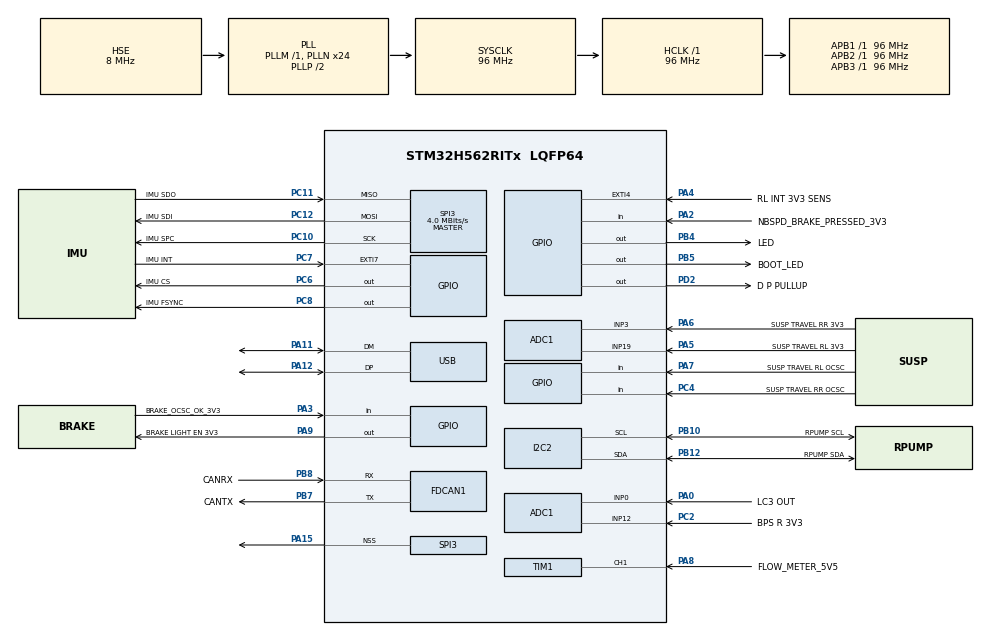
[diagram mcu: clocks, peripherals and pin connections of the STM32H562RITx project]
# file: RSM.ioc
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ADC1.Channel-0\#ChannelRegularConversion=ADC_CHANNEL_0
ADC1.Channel-1\#ChannelRegularConversion=ADC_CHANNEL_19
ADC1.Channel-2\#ChannelRegularConversion=ADC_CHANNEL_3
ADC1.Channel-3\#ChannelRegularConversion=ADC_CHANNEL_12
ADC1.ContinuousConvMode=DISABLE
ADC1.ConversionDataManagement=ADC_CONVERSIONDATA_DMA_CIRCULAR
ADC1.DMAContinuousRequests=ENABLE
ADC1.EOCSelection=ADC_EOC_SEQ_CONV
ADC1.ExternalTrigConv=ADC_EXTERNALTRIG_T3_TRGO
ADC1.MonitoredBy-0\#ChannelRegularConversion=__NULL
ADC1.MonitoredBy-1\#ChannelRegularConversion=__NULL
ADC1.MonitoredBy-2\#ChannelRegularConversion=__NULL
ADC1.MonitoredBy-3\#ChannelRegularConversion=__NULL
ADC1.NbrOfConversion=4
ADC1.NbrOfConversionFlag=1
ADC1.OffsetNumber-0\#ChannelRegularConversion=ADC_OFFSET_NONE
ADC1.OffsetNumber-1\#ChannelRegularConversion=ADC_OFFSET_NONE
ADC1.OffsetNumber-2\#ChannelRegularConversion=ADC_OFFSET_NONE
ADC1.OffsetNumber-3\#ChannelRegularConversion=ADC_OFFSET_NONE
ADC1.Rank-0\#ChannelRegularConversion=1
ADC1.Rank-1\#ChannelRegularConversion=2
ADC1.Rank-2\#ChannelRegularConversion=3
ADC1.Rank-3\#ChannelRegularConversion=4
ADC1.SamplingTime-0\#ChannelRegularConversion=ADC_SAMPLETIME_2CYCLES_5
ADC1.SamplingTime-1\#ChannelRegularConversion=ADC_SAMPLETIME_47CYCLES_5
ADC1.SamplingTime-2\#ChannelRegularConversion=ADC_SAMPLETIME_47CYCLES_5
ADC1.SamplingTime-3\#ChannelRegularConversion=ADC_SAMPLETIME_47CYCLES_5
ADC1.master=1
BOOTPATH.BootPathName=LEGACY
BOOTPATH.UserSelectedBootPath=LEGACY
CORTEX_M33_NS.userName=CORTEX_M33
FDCAN1.AutoRetransmission=ENABLE
FDCAN1.CalculateBaudRateNominal=1000000
FDCAN1.CalculateTimeBitNominal=1000
FDCAN1.CalculateTimeQuantumNominal=62.5
FDCAN1.DataPrescaler=3
FDCAN1.DataSyncJumpWidth=2
FDCAN1.DataTimeSeg1=5
FDCAN1.DataTimeSeg2=2
FDCAN1.ExtFiltersNbr=1
FDCAN1.FrameFormat=FDCAN_FRAME_FD_NO_BRS
FDCAN1.NominalPrescaler=6
FDCAN1.NominalSyncJumpWidth=2
FDCAN1.NominalTimeSeg1=13
FDCAN1.NominalTimeSeg2=2
FDCAN1.StdFiltersNbr=1
GPDMA1.CIRCULARMODE_GPDMACH0=ENABLE
GPDMA1.DESTDATAWIDTH_GPDMACH0=DMA_DEST_DATAWIDTH_HALFWORD
GPDMA1.DESTINC_GPDMACH0=DMA_DINC_INCREMENTED
GPDMA1.IPHANDLE_GPDMACH0-SIMPLEREQUEST_GPDMACH0=__NULL
GPDMA1.REQUEST_GPDMACH0=GPDMA1_REQUEST_ADC1
GPDMA1.SRCDATAWIDTH_GPDMACH0=DMA_SRC_DATAWIDTH_HALFWORD
GPDMA1.SRCINC_GPDMACH0=DMA_SINC_FIXED
I2C2.Timing=0x10B0DCFB
IWDG.Reload=LSI_FREQUENCY / IWDG_PRESCALER / IWDG_RESET_FREQUENCY
Mcu.Family=STM32H5
Mcu.Name=STM32H562RITx
Mcu.Package=LQFP64
Mcu.UserConstants=IWDG_RESET_FREQUENCY,5;TIM1_FREQUENCY,1000;TIM3_PRESCALER,250;TIM3_ARR,(TIMx_FREQUENCY / TIM3_PRESCALER / TIM3_FREQUENCY);TIM3_FREQUENCY,10000;TIM1_ARR,(TIMx_FREQUENCY / TIM1_PRESCALER / TIM1_FREQUENCY);IWDG_PRESCALER,4;LSI_FREQUENCY,32000;TIM1_PRESCALER,250;TIMx_FREQUENCY,250000000
NVIC.ADC1_IRQn=true\:5\:0\:true\:false\:true\:true\:true\:true
NVIC.FDCAN1_IT0_IRQn=true\:5\:0\:true\:false\:true\:true\:true\:true
NVIC.FDCAN1_IT1_IRQn=true\:5\:0\:true\:false\:true\:true\:true\:true
NVIC.GPDMA1_Channel0_IRQn=true\:5\:0\:true\:false\:true\:false\:true\:true
NVIC.I2C2_ER_IRQn=true\:5\:0\:true\:false\:true\:true\:true\:true
NVIC.I2C2_EV_IRQn=true\:5\:0\:true\:false\:true\:true\:true\:true
NVIC.PriorityGroup=NVIC_PRIORITYGROUP_4
NVIC.SPI3_IRQn=true\:5\:0\:true\:false\:true\:true\:true\:true
NVIC.TIM1_CC_IRQn=true\:0\:0\:false\:false\:true\:true\:true\:true
NVIC.TIM1_UP_IRQn=true\:0\:0\:false\:false\:true\:true\:true\:true
NVIC.TIM3_IRQn=true\:5\:0\:true\:false\:true\:true\:true\:true
NVIC.TIM6_IRQn=true\:15\:0\:false\:false\:true\:false\:true\:true
NVIC.TIM7_IRQn=true\:5\:0\:true\:false\:true\:true\:true\:true
NVIC.TimeBase=TIM6_IRQn
NVIC.TimeBaseIP=TIM6
NVIC.USB_DRD_FS_IRQn=true\:5\:0\:true\:false\:true\:true\:true\:true
PA0.GPIO_Label=LC3 OUT
PA0.Signal=ADCx_INP0
PA11.Mode=Device
PA11.Signal=USB_DM
PA12.Mode=Device
PA12.Signal=USB_DP
PA13(JTMS/SWDIO).Mode=Trace_Asynchronous_SW
PA13(JTMS/SWDIO).Signal=DEBUG_JTMS-SWDIO
PA14(JTCK/SWCLK).Mode=Trace_Asynchronous_SW
PA14(JTCK/SWCLK).Signal=DEBUG_JTCK-SWCLK
PA15(JTDI).Mode=NSS_Signal_Hard_Output
PA15(JTDI).Signal=SPI3_NSS
PA2.GPIO_Label=NBSPD_BRAKE_PRESSED_3V3
PA2.Signal=GPIO_Input
PA3.GPIO_Label=BRAKE_OCSC_OK_3V3
PA3.Signal=GPIO_Input
PA4.GPIO_Label=RL INT 3V3 SENS
PA4.Signal=GPXTI4
PA5.GPIO_Label=SUSP TRAVEL RL 3V3
PA5.Signal=ADCx_INP19
PA6.GPIO_Label=SUSP TRAVEL RR 3V3
PA6.Signal=ADCx_INP3
PA7.GPIO_Label=SUSP TRAVEL RL OCSC
PA7.Signal=GPIO_Input
PA8.GPIO_Label=FLOW_METER_5V5
PA8.Signal=S_TIM1_CH1
PA9.GPIO_Label=BRAKE LIGHT EN 3V3
PA9.Signal=GPIO_Output
PB10.GPIO_Label=RPUMP SCL
PB10.Mode=I2C
PB10.Signal=I2C2_SCL
PB12.GPIO_Label=RPUMP SDA
PB12.Mode=I2C
PB12.Signal=I2C2_SDA
PB3(JTDO/TRACESWO).Mode=Trace_Asynchronous_SW
PB3(JTDO/TRACESWO).Signal=DEBUG_JTDO-SWO
PB4(NJTRST).GPIO_Label=LED
PB4(NJTRST).Signal=GPIO_Output
PB5.GPIO_Label=BOOT_LED
PB5.Signal=GPIO_Output
PB7.GPIO_Label=CANTX
PB7.Mode=FDCAN_Activate
PB7.Signal=FDCAN1_TX
PB8.GPIO_Label=CANRX
PB8.Mode=FDCAN_Activate
PB8.Signal=FDCAN1_RX
PC10.GPIO_Label=IMU SPC
PC10.Mode=Full_Duplex_Master
PC10.Signal=SPI3_SCK
PC11.GPIO_Label=IMU SDO
PC11.Mode=Full_Duplex_Master
PC11.Signal=SPI3_MISO
PC12.GPIO_Label=IMU SDI
PC12.Mode=Full_Duplex_Master
PC12.Signal=SPI3_MOSI
PC2.GPIO_Label=BPS R 3V3
PC2.Signal=ADCx_INP12
PC4.GPIO_Label=SUSP TRAVEL RR OCSC
PC4.Signal=GPIO_Input
PC6.GPIO_Label=IMU CS
PC6.Signal=GPIO_Output
PC7.GPIO_Label=IMU INT
PC7.Signal=GPXTI7
PC8.GPIO_Label=IMU FSYNC
PC8.Signal=GPIO_Output
PD2.GPIO_Label=D P PULLUP
PD2.Signal=GPIO_Output
PH0-OSC_IN(PH0).Mode=HSE-External-Oscillator
PH0-OSC_IN(PH0).Signal=RCC_OSC_IN
PH1-OSC_OUT(PH1).Mode=HSE-External-Oscillator
PH1-OSC_OUT(PH1).Signal=RCC_OSC_OUT
ProjectManager.HeapSize=0x200
ProjectManager.StackSize=0x400
ProjectManager.TargetToolchain=EWARM V9.20
RCC.ADCFreq_Value=96000000
RCC.AHBFreq_Value=96000000
RCC.APB1Freq_Value=96000000
RCC.APB1TimFreq_Value=96000000
RCC.APB2Freq_Value=96000000
RCC.APB2TimFreq_Value=96000000
RCC.APB3Freq_Value=96000000
RCC.CSI_VALUE=4000000
RCC.CortexFreq_Value=96000000
RCC.EPOD_VALUE=8000000
RCC.FDCANClockSelection=RCC_FDCANCLKSOURCE_PLL1Q
RCC.HCLKFreq_Value=96000000
RCC.HSE_VALUE=8000000
RCC.HSI48_VALUE=48000000
RCC.HSI_VALUE=64000000
RCC.LSE_VALUE=32768
RCC.LSIRC_VALUE=32000
RCC.PLL2FRACN=0
RCC.PLL2N=32
RCC.PLL2P=16
RCC.PLL3FRACN=0
RCC.PLLFRACN=0
RCC.PLLN=24
RCC.PLLSourceVirtual=RCC_PLL1_SOURCE_HSE
RCC.SPI3CLockSelection=RCC_SPI3CLKSOURCE_PLL2P
RCC.SYSCLKFreq_VALUE=96000000
RCC.SYSCLKSource=RCC_SYSCLKSOURCE_PLLCLK
RCC.USBFreq_Value=48000000
RCC.VCOOutputFreq_Value=192000000
SH.ADCx_INP0.0=ADC1_INP0,IN0-Single-Ended
SH.ADCx_INP12.0=ADC1_INP12,IN12-Single-Ended
SH.ADCx_INP19.0=ADC1_INP19,IN19-Single-Ended
SH.ADCx_INP3.0=ADC1_INP3,IN3-Single-Ended
SH.S_TIM1_CH1.0=TIM1_CH1,Input_Capture1_from_TI1
SPI3.BaudRatePrescaler=SPI_BAUDRATEPRESCALER_2
SPI3.CalculateBaudRate=4.0 MBits/s
SPI3.DataSize=SPI_DATASIZE_8BIT
SPI3.Direction=SPI_DIRECTION_2LINES
SPI3.Mode=SPI_MODE_MASTER
SPI3.VirtualNSS=VM_NSSHARD
SPI3.VirtualType=VM_MASTER
TIM1.Channel-Input_Capture1_from_TI1=TIM_CHANNEL_1
TIM1.Channel-Input_Capture2_from_TI1_63=TIM_CHANNEL_2
TIM1.ICPolarity_CH2=TIM_INPUTCHANNELPOLARITY_FALLING
TIM1.PeriodNoDither=TIM1_ARR - 1
TIM1.Prescaler=TIM1_PRESCALER - 1
TIM3.AutoReloadPreload=TIM_AUTORELOAD_PRELOAD_ENABLE
TIM3.PeriodNoDither=TIM3_ARR - 1
TIM3.Prescaler=TIM3_PRESCALER - 1
TIM3.TIM_MasterOutputTrigger=TIM_TRGO_UPDATE
TIM3.TIM_MasterSlaveMode=TIM_MASTERSLAVEMODE_DISABLE
TIM7.PeriodNoDither=960-1
TIM7.Prescaler=10-1
USB.VirtualMode=Device_Only
VP_BOOTPATH_VS_BOOTPATH.Mode=BP_Activate
VP_CORTEX_M33_NS_VS_Hclk.Mode=Hclk_Mode
VP_GPDMA1_VS_GPDMACH0.Mode=SIMPLEREQUEST_GPDMACH0
VP_IWDG_VS_IWDG.Mode=IWDG_Activate
VP_MEMORYMAP_VS_MEMORYMAP.Mode=CurAppReg
VP_PWR_VS_LPOM.Mode=PowerOptimisation
VP_PWR_VS_SECSignals.Mode=Security/Privilege
VP_SYS_VS_tim6.Mode=TIM6
VP_TIM1_VS_ClockSourceINT.Mode=Internal
VP_TIM1_VS_indirect_ch1.Mode=Input_Capture2_from_TI1_63
VP_TIM3_VS_ClockSourceINT.Mode=Internal
VP_TIM7_VS_ClockSourceINT.Mode=Enable_Timer
board=custom

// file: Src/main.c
/* USER CODE BEGIN Header */
/**
 ******************************************************************************
 * @file           : main.c
 * @brief          : Main program body
 ******************************************************************************
 * @attention
 *
 * Copyright (c) 2025 STMicroelectronics.
 * All rights reserved.
 *
 * This software is licensed under terms that can be found in the LICENSE file
 * in the root directory of this software component.
 * If no LICENSE file comes with this software, it is provided AS-IS.
 *
 ******************************************************************************
 */
/* USER CODE END Header */
#include "main.h"

/* USER CODE BEGIN Includes */
#include "tasks.h"
#include <stm32h5xx_hal.h>
#include <stm32h5xx_hal_gpio.h>
#include "hw_error.hpp"
/* USER CODE END Includes */

ADC_HandleTypeDef hadc1;
DMA_NodeTypeDef   Node_GPDMA1_Channel0;
DMA_QListTypeDef  List_GPDMA1_Channel0;
DMA_HandleTypeDef handle_GPDMA1_Channel0;

FDCAN_HandleTypeDef hfdcan1;

I2C_HandleTypeDef hi2c2;

IWDG_HandleTypeDef hiwdg;

SPI_HandleTypeDef hspi3;

TIM_HandleTypeDef htim1;
TIM_HandleTypeDef htim3;
TIM_HandleTypeDef htim7;

PCD_HandleTypeDef hpcd_USB_DRD_FS;

void        SystemClock_Config(void);
static void MX_GPIO_Init(void);
static void MX_GPDMA1_Init(void);
static void MX_ADC1_Init(void);
static void MX_FDCAN1_Init(void);
static void MX_I2C2_Init(void);
static void MX_SPI3_Init(void);
static void MX_USB_PCD_Init(void);
static void MX_TIM1_Init(void);
static void MX_TIM3_Init(void);
static void MX_IWDG_Init(void);
static void MX_TIM7_Init(void);

int main(void)
{
    /* USER CODE BEGIN 1 */
    tasks_preInit();
    /* USER CODE END 1 */

    /* MCU Configuration--------------------------------------------------------*/

    /* Reset of all peripherals, Initializes the Flash interface and the Systick. */
    HAL_Init();

    /* Configure the system clock */
    SystemClock_Config();

    /* Initialize all configured peripherals */
    MX_GPIO_Init();
    MX_GPDMA1_Init();
    MX_ADC1_Init();
    MX_FDCAN1_Init();
    MX_I2C2_Init();
    MX_SPI3_Init();
    MX_USB_PCD_Init();
    MX_TIM1_Init();
    MX_TIM3_Init();
    MX_IWDG_Init();
    MX_TIM7_Init();
    /* USER CODE BEGIN 2 */
    HAL_GPIO_WritePin(BRAKE_LIGHT_EN_3V3_GPIO_Port, BRAKE_LIGHT_EN_3V3_Pin, GPIO_PIN_RESET);
    ;
    tasks_init();
    /* USER CODE END 2 */

    /* Infinite loop */
    while (1)
    {

    }
}

void SystemClock_Config(void)
{
    RCC_OscInitTypeDef RCC_OscInitStruct = { 0 };
    RCC_ClkInitTypeDef RCC_ClkInitStruct = { 0 };

    /** Configure the main internal regulator output voltage
     */
    __HAL_PWR_VOLTAGESCALING_CONFIG(PWR_REGULATOR_VOLTAGE_SCALE3);

    while (!__HAL_PWR_GET_FLAG(PWR_FLAG_VOSRDY))
    {
    }

    /** Initializes the RCC Oscillators according to the specified parameters
     * in the RCC_OscInitTypeDef structure.
     */
    RCC_OscInitStruct.OscillatorType =
        RCC_OSCILLATORTYPE_HSI48 | RCC_OSCILLATORTYPE_LSI | RCC_OSCILLATORTYPE_HSE | RCC_OSCILLATORTYPE_CSI;
    RCC_OscInitStruct.HSEState            = RCC_HSE_ON;
    RCC_OscInitStruct.LSIState            = RCC_LSI_ON;
    RCC_OscInitStruct.HSI48State          = RCC_HSI48_ON;
    RCC_OscInitStruct.CSIState            = RCC_CSI_ON;
    RCC_OscInitStruct.CSICalibrationValue = RCC_CSICALIBRATION_DEFAULT;
    RCC_OscInitStruct.PLL.PLLState        = RCC_PLL_ON;
    RCC_OscInitStruct.PLL.PLLSource       = RCC_PLL1_SOURCE_HSE;
    RCC_OscInitStruct.PLL.PLLM            = 1;
    RCC_OscInitStruct.PLL.PLLN            = 24;
    RCC_OscInitStruct.PLL.PLLP            = 2;
    RCC_OscInitStruct.PLL.PLLQ            = 2;
    RCC_OscInitStruct.PLL.PLLR            = 2;
    RCC_OscInitStruct.PLL.PLLRGE          = RCC_PLL1_VCIRANGE_3;
    RCC_OscInitStruct.PLL.PLLVCOSEL       = RCC_PLL1_VCORANGE_WIDE;
    RCC_OscInitStruct.PLL.PLLFRACN        = 0;
    if (HAL_RCC_OscConfig(&RCC_OscInitStruct) != HAL_OK)
    {
        Error_Handler();
    }

    /** Initializes the CPU, AHB and APB buses clocks
     */
    RCC_ClkInitStruct.ClockType =
        RCC_CLOCKTYPE_HCLK | RCC_CLOCKTYPE_SYSCLK | RCC_CLOCKTYPE_PCLK1 | RCC_CLOCKTYPE_PCLK2 | RCC_CLOCKTYPE_PCLK3;
    RCC_ClkInitStruct.SYSCLKSource   = RCC_SYSCLKSOURCE_PLLCLK;
    RCC_ClkInitStruct.AHBCLKDivider  = RCC_SYSCLK_DIV1;
    RCC_ClkInitStruct.APB1CLKDivider = RCC_HCLK_DIV1;
    RCC_ClkInitStruct.APB2CLKDivider = RCC_HCLK_DIV1;
    RCC_ClkInitStruct.APB3CLKDivider = RCC_HCLK_DIV1;

    if (HAL_RCC_ClockConfig(&RCC_ClkInitStruct, FLASH_LATENCY_4) != HAL_OK)
    {
        Error_Handler();
    }

    /** Configure the programming delay
     */
    __HAL_FLASH_SET_PROGRAM_DELAY(FLASH_PROGRAMMING_DELAY_2);
}

static void MX_ADC1_Init(void)
{

    ADC_ChannelConfTypeDef sConfig = { 0 };

    /** Common config
     */
    hadc1.Instance                   = ADC1;
    hadc1.Init.ClockPrescaler        = ADC_CLOCK_ASYNC_DIV2;
    hadc1.Init.Resolution            = ADC_RESOLUTION_12B;
    hadc1.Init.DataAlign             = ADC_DATAALIGN_RIGHT;
    hadc1.Init.ScanConvMode          = ADC_SCAN_ENABLE;
    hadc1.Init.EOCSelection          = ADC_EOC_SEQ_CONV;
    hadc1.Init.LowPowerAutoWait      = DISABLE;
    hadc1.Init.ContinuousConvMode    = DISABLE;
    hadc1.Init.NbrOfConversion       = 4;
    hadc1.Init.DiscontinuousConvMode = DISABLE;
    hadc1.Init.ExternalTrigConv      = ADC_EXTERNALTRIG_T3_TRGO;
    hadc1.Init.ExternalTrigConvEdge  = ADC_EXTERNALTRIGCONVEDGE_RISING;
    hadc1.Init.DMAContinuousRequests = ENABLE;
    hadc1.Init.SamplingMode          = ADC_SAMPLING_MODE_NORMAL;
    hadc1.Init.Overrun               = ADC_OVR_DATA_PRESERVED;
    hadc1.Init.OversamplingMode      = DISABLE;
    if (HAL_ADC_Init(&hadc1) != HAL_OK)
    {
        Error_Handler();
    }

    /** Configure Regular Channel
     */
    sConfig.Channel      = ADC_CHANNEL_0;
    sConfig.Rank         = ADC_REGULAR_RANK_1;
    sConfig.SamplingTime = ADC_SAMPLETIME_2CYCLES_5;
    sConfig.SingleDiff   = ADC_SINGLE_ENDED;
    sConfig.OffsetNumber = ADC_OFFSET_NONE;
    sConfig.Offset       = 0;
    if (HAL_ADC_ConfigChannel(&hadc1, &sConfig) != HAL_OK)
    {
        Error_Handler();
    }

    /** Configure Regular Channel
     */
    sConfig.Channel      = ADC_CHANNEL_19;
    sConfig.Rank         = ADC_REGULAR_RANK_2;
    sConfig.SamplingTime = ADC_SAMPLETIME_47CYCLES_5;
    if (HAL_ADC_ConfigChannel(&hadc1, &sConfig) != HAL_OK)
    {
        Error_Handler();
    }

    /** Configure Regular Channel
     */
    sConfig.Channel = ADC_CHANNEL_3;
    sConfig.Rank    = ADC_REGULAR_RANK_3;
    if (HAL_ADC_ConfigChannel(&hadc1, &sConfig) != HAL_OK)
    {
        Error_Handler();
    }

    /** Configure Regular Channel
     */
    sConfig.Channel = ADC_CHANNEL_12;
    sConfig.Rank    = ADC_REGULAR_RANK_4;
    if (HAL_ADC_ConfigChannel(&hadc1, &sConfig) != HAL_OK)
    {
        Error_Handler();
    }
}

static void MX_FDCAN1_Init(void)
{

    hfdcan1.Instance                  = FDCAN1;
    hfdcan1.Init.ClockDivider         = FDCAN_CLOCK_DIV1;
    hfdcan1.Init.FrameFormat          = FDCAN_FRAME_FD_BRS;
    hfdcan1.Init.Mode                 = FDCAN_MODE_NORMAL;
    hfdcan1.Init.AutoRetransmission   = ENABLE;
    hfdcan1.Init.TransmitPause        = ENABLE;
    hfdcan1.Init.ProtocolException    = ENABLE;
    hfdcan1.Init.NominalPrescaler     = 1;
    hfdcan1.Init.NominalSyncJumpWidth = 15;
    hfdcan1.Init.NominalTimeSeg1      = 80;
    hfdcan1.Init.NominalTimeSeg2      = 15;
    hfdcan1.Init.DataPrescaler        = 1;
    hfdcan1.Init.DataSyncJumpWidth    = 4;
    hfdcan1.Init.DataTimeSeg1         = 19;
    hfdcan1.Init.DataTimeSeg2         = 4;
    hfdcan1.Init.StdFiltersNbr        = 1;
    hfdcan1.Init.ExtFiltersNbr        = 1;
    hfdcan1.Init.TxFifoQueueMode      = FDCAN_TX_FIFO_OPERATION;
    if (HAL_FDCAN_Init(&hfdcan1) != HAL_OK)
    {
        Error_Handler();
    }
    /* USER CODE BEGIN FDCAN1_Init 2 */
    HAL_FDCAN_ConfigTxDelayCompensation(&hfdcan1, 15, 0);
    HAL_FDCAN_EnableTxDelayCompensation(&hfdcan1);
    /* USER CODE END FDCAN1_Init 2 */
}

static void MX_GPDMA1_Init(void)
{

    /* Peripheral clock enable */
    __HAL_RCC_GPDMA1_CLK_ENABLE();

    /* GPDMA1 interrupt Init */
    HAL_NVIC_SetPriority(GPDMA1_Channel0_IRQn, 5, 0);
    HAL_NVIC_EnableIRQ(GPDMA1_Channel0_IRQn);

}

static void MX_I2C2_Init(void)
{

    hi2c2.Instance              = I2C2;
    hi2c2.Init.Timing           = 0x10B0DCFB;
    hi2c2.Init.OwnAddress1      = 0;
    hi2c2.Init.AddressingMode   = I2C_ADDRESSINGMODE_7BIT;
    hi2c2.Init.DualAddressMode  = I2C_DUALADDRESS_DISABLE;
    hi2c2.Init.OwnAddress2      = 0;
    hi2c2.Init.OwnAddress2Masks = I2C_OA2_NOMASK;
    hi2c2.Init.GeneralCallMode  = I2C_GENERALCALL_DISABLE;
    hi2c2.Init.NoStretchMode    = I2C_NOSTRETCH_DISABLE;
    if (HAL_I2C_Init(&hi2c2) != HAL_OK)
    {
        Error_Handler();
    }

    /** Configure Analogue filter
     */
    if (HAL_I2CEx_ConfigAnalogFilter(&hi2c2, I2C_ANALOGFILTER_ENABLE) != HAL_OK)
    {
        Error_Handler();
    }

    /** Configure Digital filter
     */
    if (HAL_I2CEx_ConfigDigitalFilter(&hi2c2, 0) != HAL_OK)
    {
        Error_Handler();
    }
}

static void MX_IWDG_Init(void)
{

    /* USER CODE BEGIN IWDG_Init 1 */
#ifndef WATCHDOG_DISABLED
    /* USER CODE END IWDG_Init 1 */
    hiwdg.Instance       = IWDG;
    hiwdg.Init.Prescaler = IWDG_PRESCALER_4;
    hiwdg.Init.Window    = 4095;
    hiwdg.Init.Reload    = LSI_FREQUENCY / IWDG_PRESCALER / IWDG_RESET_FREQUENCY;
    hiwdg.Init.EWI       = 0;
    if (HAL_IWDG_Init(&hiwdg) != HAL_OK)
    {
        Error_Handler();
    }
    /* USER CODE BEGIN IWDG_Init 2 */
#endif
    /* USER CODE END IWDG_Init 2 */
}

static void MX_SPI3_Init(void)
{

    /* SPI3 parameter configuration*/
    hspi3.Instance                     = SPI3;
    hspi3.Init.Mode                    = SPI_MODE_MASTER;
    hspi3.Init.Direction               = SPI_DIRECTION_2LINES;
    hspi3.Init.DataSize                = SPI_DATASIZE_8BIT;
    hspi3.Init.CLKPolarity             = SPI_POLARITY_LOW;
    hspi3.Init.CLKPhase                = SPI_PHASE_1EDGE;
    hspi3.Init.NSS                     = SPI_NSS_HARD_OUTPUT;
    hspi3.Init.BaudRatePrescaler       = SPI_BAUDRATEPRESCALER_2;
    hspi3.Init.FirstBit                = SPI_FIRSTBIT_MSB;
    hspi3.Init.TIMode                  = SPI_TIMODE_DISABLE;
    hspi3.Init.CRCCalculation          = SPI_CRCCALCULATION_DISABLE;
    hspi3.Init.CRCPolynomial           = 0x7;
    hspi3.Init.NSSPMode                = SPI_NSS_PULSE_ENABLE;
    hspi3.Init.NSSPolarity             = SPI_NSS_POLARITY_LOW;
    hspi3.Init.FifoThreshold           = SPI_FIFO_THRESHOLD_01DATA;
    hspi3.Init.MasterSSIdleness        = SPI_MASTER_SS_IDLENESS_00CYCLE;
    hspi3.Init.MasterInterDataIdleness = SPI_MASTER_INTERDATA_IDLENESS_00CYCLE;
    hspi3.Init.MasterReceiverAutoSusp  = SPI_MASTER_RX_AUTOSUSP_DISABLE;
    hspi3.Init.MasterKeepIOState       = SPI_MASTER_KEEP_IO_STATE_DISABLE;
    hspi3.Init.IOSwap                  = SPI_IO_SWAP_DISABLE;
    hspi3.Init.ReadyMasterManagement   = SPI_RDY_MASTER_MANAGEMENT_INTERNALLY;
    hspi3.Init.ReadyPolarity           = SPI_RDY_POLARITY_HIGH;
    if (HAL_SPI_Init(&hspi3) != HAL_OK)
    {
        Error_Handler();
    }
}

static void MX_TIM1_Init(void)
{

    TIM_ClockConfigTypeDef  sClockSourceConfig = { 0 };
    TIM_MasterConfigTypeDef sMasterConfig      = { 0 };
    TIM_IC_InitTypeDef      sConfigIC          = { 0 };

    htim1.Instance               = TIM1;
    htim1.Init.Prescaler         = TIM1_PRESCALER - 1;
    htim1.Init.CounterMode       = TIM_COUNTERMODE_UP;
    htim1.Init.Period            = 999;
    htim1.Init.ClockDivision     = TIM_CLOCKDIVISION_DIV1;
    htim1.Init.RepetitionCounter = 0;
    htim1.Init.AutoReloadPreload = TIM_AUTORELOAD_PRELOAD_DISABLE;
    if (HAL_TIM_Base_Init(&htim1) != HAL_OK)
    {
        Error_Handler();
    }
    sClockSourceConfig.ClockSource = TIM_CLOCKSOURCE_INTERNAL;
    if (HAL_TIM_ConfigClockSource(&htim1, &sClockSourceConfig) != HAL_OK)
    {
        Error_Handler();
    }
    if (HAL_TIM_IC_Init(&htim1) != HAL_OK)
    {
        Error_Handler();
    }
    sMasterConfig.MasterOutputTrigger  = TIM_TRGO_RESET;
    sMasterConfig.MasterOutputTrigger2 = TIM_TRGO2_RESET;
    sMasterConfig.MasterSlaveMode      = TIM_MASTERSLAVEMODE_DISABLE;
    if (HAL_TIMEx_MasterConfigSynchronization(&htim1, &sMasterConfig) != HAL_OK)
    {
        Error_Handler();
    }
    sConfigIC.ICPolarity  = TIM_INPUTCHANNELPOLARITY_RISING;
    sConfigIC.ICSelection = TIM_ICSELECTION_DIRECTTI;
    sConfigIC.ICPrescaler = TIM_ICPSC_DIV1;
    sConfigIC.ICFilter    = 0;
    if (HAL_TIM_IC_ConfigChannel(&htim1, &sConfigIC, TIM_CHANNEL_1) != HAL_OK)
    {
        Error_Handler();
    }
    sConfigIC.ICPolarity  = TIM_INPUTCHANNELPOLARITY_FALLING;
    sConfigIC.ICSelection = TIM_ICSELECTION_INDIRECTTI;
    if (HAL_TIM_IC_ConfigChannel(&htim1, &sConfigIC, TIM_CHANNEL_2) != HAL_OK)
    {
        Error_Handler();
    }
}

static void MX_TIM3_Init(void)
{

    TIM_ClockConfigTypeDef  sClockSourceConfig = { 0 };
    TIM_MasterConfigTypeDef sMasterConfig      = { 0 };

    htim3.Instance               = TIM3;
    htim3.Init.Prescaler         = TIM3_PRESCALER - 1;
    htim3.Init.CounterMode       = TIM_COUNTERMODE_UP;
    htim3.Init.Period            = 99;
    htim3.Init.ClockDivision     = TIM_CLOCKDIVISION_DIV1;
    htim3.Init.AutoReloadPreload = TIM_AUTORELOAD_PRELOAD_ENABLE;
    if (HAL_TIM_Base_Init(&htim3) != HAL_OK)
    {
        Error_Handler();
    }
    sClockSourceConfig.ClockSource = TIM_CLOCKSOURCE_INTERNAL;
    if (HAL_TIM_ConfigClockSource(&htim3, &sClockSourceConfig) != HAL_OK)
    {
        Error_Handler();
    }
    sMasterConfig.MasterOutputTrigger = TIM_TRGO_UPDATE;
    sMasterConfig.MasterSlaveMode     = TIM_MASTERSLAVEMODE_DISABLE;
    if (HAL_TIMEx_MasterConfigSynchronization(&htim3, &sMasterConfig) != HAL_OK)
    {
        Error_Handler();
    }
}

static void MX_TIM7_Init(void)
{

    TIM_MasterConfigTypeDef sMasterConfig = { 0 };

    htim7.Instance               = TIM7;
    htim7.Init.Prescaler         = 10 - 1;
    htim7.Init.CounterMode       = TIM_COUNTERMODE_UP;
    htim7.Init.Period            = 959;
    htim7.Init.AutoReloadPreload = TIM_AUTORELOAD_PRELOAD_DISABLE;
    if (HAL_TIM_Base_Init(&htim7) != HAL_OK)
    {
        Error_Handler();
    }
    sMasterConfig.MasterOutputTrigger = TIM_TRGO_RESET;
    sMasterConfig.MasterSlaveMode     = TIM_MASTERSLAVEMODE_DISABLE;
    if (HAL_TIMEx_MasterConfigSynchronization(&htim7, &sMasterConfig) != HAL_OK)
    {
        Error_Handler();
    }
}

static void MX_USB_PCD_Init(void)
{

    hpcd_USB_DRD_FS.Instance                      = USB_DRD_FS;
    hpcd_USB_DRD_FS.Init.dev_endpoints            = 8;
    hpcd_USB_DRD_FS.Init.speed                    = USBD_FS_SPEED;
    hpcd_USB_DRD_FS.Init.phy_itface               = PCD_PHY_EMBEDDED;
    hpcd_USB_DRD_FS.Init.Sof_enable               = DISABLE;
    hpcd_USB_DRD_FS.Init.low_power_enable         = DISABLE;
    hpcd_USB_DRD_FS.Init.lpm_enable               = DISABLE;
    hpcd_USB_DRD_FS.Init.battery_charging_enable  = DISABLE;
    hpcd_USB_DRD_FS.Init.vbus_sensing_enable      = DISABLE;
    hpcd_USB_DRD_FS.Init.bulk_doublebuffer_enable = DISABLE;
    hpcd_USB_DRD_FS.Init.iso_singlebuffer_enable  = DISABLE;
    if (HAL_PCD_Init(&hpcd_USB_DRD_FS) != HAL_OK)
    {
        Error_Handler();
    }
}

static void MX_GPIO_Init(void)
{
    GPIO_InitTypeDef GPIO_InitStruct = { 0 };

    /* GPIO Ports Clock Enable */
    __HAL_RCC_GPIOH_CLK_ENABLE();
    __HAL_RCC_GPIOC_CLK_ENABLE();
    __HAL_RCC_GPIOA_CLK_ENABLE();
    __HAL_RCC_GPIOB_CLK_ENABLE();
    __HAL_RCC_GPIOD_CLK_ENABLE();

    /*Configure GPIO pin Output Level */
    HAL_GPIO_WritePin(GPIOC, IMU_CS_Pin | IMU_FSYNC_Pin, GPIO_PIN_RESET);

    /*Configure GPIO pin Output Level */
    HAL_GPIO_WritePin(BRAKE_LIGHT_EN_3V3_GPIO_Port, BRAKE_LIGHT_EN_3V3_Pin, GPIO_PIN_RESET);

    /*Configure GPIO pin Output Level */
    HAL_GPIO_WritePin(D_P_PULLUP_GPIO_Port, D_P_PULLUP_Pin, GPIO_PIN_RESET);

    /*Configure GPIO pin Output Level */
    HAL_GPIO_WritePin(GPIOB, LED_Pin | BOOT_LED_Pin, GPIO_PIN_RESET);

    /*Configure GPIO pins : NBSPD_BRAKE_PRESSED_3V3_Pin BRAKE_OCSC_OK_3V3_Pin SUSP_TRAVEL_RL_OCSC_Pin */
    GPIO_InitStruct.Pin  = NBSPD_BRAKE_PRESSED_3V3_Pin | BRAKE_OCSC_OK_3V3_Pin | SUSP_TRAVEL_RL_OCSC_Pin;
    GPIO_InitStruct.Mode = GPIO_MODE_INPUT;
    GPIO_InitStruct.Pull = GPIO_NOPULL;
    HAL_GPIO_Init(GPIOA, &GPIO_InitStruct);

    /*Configure GPIO pin : RL_INT_3V3_SENS_Pin */
    GPIO_InitStruct.Pin  = RL_INT_3V3_SENS_Pin;
    GPIO_InitStruct.Mode = GPIO_MODE_IT_RISING;
    GPIO_InitStruct.Pull = GPIO_NOPULL;
    HAL_GPIO_Init(RL_INT_3V3_SENS_GPIO_Port, &GPIO_InitStruct);

    /*Configure GPIO pin : SUSP_TRAVEL_RR_OCSC_Pin */
    GPIO_InitStruct.Pin  = SUSP_TRAVEL_RR_OCSC_Pin;
    GPIO_InitStruct.Mode = GPIO_MODE_INPUT;
    GPIO_InitStruct.Pull = GPIO_NOPULL;
    HAL_GPIO_Init(SUSP_TRAVEL_RR_OCSC_GPIO_Port, &GPIO_InitStruct);

    /*Configure GPIO pins : IMU_CS_Pin IMU_FSYNC_Pin */
    GPIO_InitStruct.Pin   = IMU_CS_Pin | IMU_FSYNC_Pin;
    GPIO_InitStruct.Mode  = GPIO_MODE_OUTPUT_PP;
    GPIO_InitStruct.Pull  = GPIO_NOPULL;
    GPIO_InitStruct.Speed = GPIO_SPEED_FREQ_LOW;
    HAL_GPIO_Init(GPIOC, &GPIO_InitStruct);

    /*Configure GPIO pin : IMU_INT_Pin */
    GPIO_InitStruct.Pin  = IMU_INT_Pin;
    GPIO_InitStruct.Mode = GPIO_MODE_IT_RISING;
    GPIO_InitStruct.Pull = GPIO_NOPULL;
    HAL_GPIO_Init(IMU_INT_GPIO_Port, &GPIO_InitStruct);

    /*Configure GPIO pin : BRAKE_LIGHT_EN_3V3_Pin */
    GPIO_InitStruct.Pin   = BRAKE_LIGHT_EN_3V3_Pin;
    GPIO_InitStruct.Mode  = GPIO_MODE_OUTPUT_PP;
    GPIO_InitStruct.Pull  = GPIO_NOPULL;
    GPIO_InitStruct.Speed = GPIO_SPEED_FREQ_LOW;
    HAL_GPIO_Init(BRAKE_LIGHT_EN_3V3_GPIO_Port, &GPIO_InitStruct);

    /*Configure GPIO pin : D_P_PULLUP_Pin */
    GPIO_InitStruct.Pin   = D_P_PULLUP_Pin;
    GPIO_InitStruct.Mode  = GPIO_MODE_OUTPUT_PP;
    GPIO_InitStruct.Pull  = GPIO_NOPULL;
    GPIO_InitStruct.Speed = GPIO_SPEED_FREQ_LOW;
    HAL_GPIO_Init(D_P_PULLUP_GPIO_Port, &GPIO_InitStruct);

    /*Configure GPIO pins : LED_Pin BOOT_LED_Pin */
    GPIO_InitStruct.Pin   = LED_Pin | BOOT_LED_Pin;
    GPIO_InitStruct.Mode  = GPIO_MODE_OUTPUT_PP;
    GPIO_InitStruct.Pull  = GPIO_NOPULL;
    GPIO_InitStruct.Speed = GPIO_SPEED_FREQ_LOW;
    HAL_GPIO_Init(GPIOB, &GPIO_InitStruct);

}

void HAL_TIM_PeriodElapsedCallback(TIM_HandleTypeDef *htim)
{
    if (htim->Instance == TIM6)
    {
        HAL_IncTick();
    }
    /* USER CODE BEGIN Callback 1 */
    tasks_handle_arr_rollover_callback(htim);
    /* USER CODE END Callback 1 */
}

void Error_Handler(void)
{
    __disable_irq();
    while (1)
    {
    }
}
